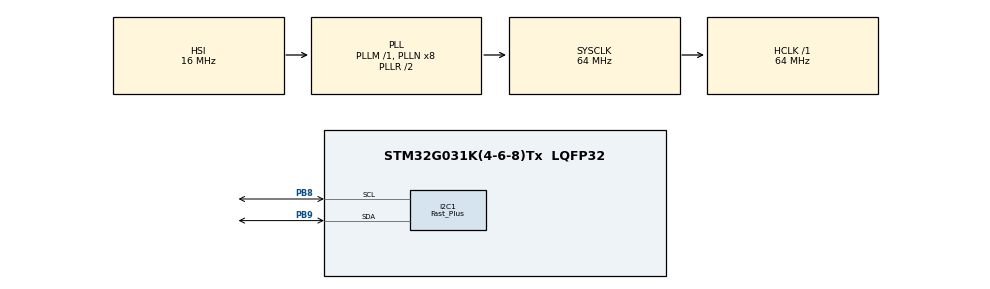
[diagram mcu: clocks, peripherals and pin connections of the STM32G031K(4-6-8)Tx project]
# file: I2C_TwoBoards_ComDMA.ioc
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Dma.I2C1_RX.1.Direction=DMA_PERIPH_TO_MEMORY
Dma.I2C1_RX.1.EventEnable=DISABLE
Dma.I2C1_RX.1.Instance=DMA1_Channel2
Dma.I2C1_RX.1.MemDataAlignment=DMA_MDATAALIGN_BYTE
Dma.I2C1_RX.1.MemInc=DMA_MINC_ENABLE
Dma.I2C1_RX.1.Mode=DMA_NORMAL
Dma.I2C1_RX.1.PeriphDataAlignment=DMA_PDATAALIGN_BYTE
Dma.I2C1_RX.1.PeriphInc=DMA_PINC_DISABLE
Dma.I2C1_RX.1.Polarity=HAL_DMAMUX_REQ_GEN_RISING
Dma.I2C1_RX.1.Priority=DMA_PRIORITY_HIGH
Dma.I2C1_RX.1.RequestNumber=1
Dma.I2C1_RX.1.SignalID=NONE
Dma.I2C1_RX.1.SyncEnable=DISABLE
Dma.I2C1_RX.1.SyncPolarity=HAL_DMAMUX_SYNC_NO_EVENT
Dma.I2C1_RX.1.SyncRequestNumber=1
Dma.I2C1_RX.1.SyncSignalID=NONE
Dma.I2C1_TX.0.Direction=DMA_MEMORY_TO_PERIPH
Dma.I2C1_TX.0.EventEnable=DISABLE
Dma.I2C1_TX.0.Instance=DMA1_Channel1
Dma.I2C1_TX.0.MemDataAlignment=DMA_MDATAALIGN_BYTE
Dma.I2C1_TX.0.MemInc=DMA_MINC_ENABLE
Dma.I2C1_TX.0.Mode=DMA_NORMAL
Dma.I2C1_TX.0.PeriphDataAlignment=DMA_PDATAALIGN_BYTE
Dma.I2C1_TX.0.PeriphInc=DMA_PINC_DISABLE
Dma.I2C1_TX.0.Polarity=HAL_DMAMUX_REQ_GEN_RISING
Dma.I2C1_TX.0.Priority=DMA_PRIORITY_LOW
Dma.I2C1_TX.0.RequestNumber=1
Dma.I2C1_TX.0.SignalID=NONE
Dma.I2C1_TX.0.SyncEnable=DISABLE
Dma.I2C1_TX.0.SyncPolarity=HAL_DMAMUX_SYNC_NO_EVENT
Dma.I2C1_TX.0.SyncRequestNumber=1
Dma.I2C1_TX.0.SyncSignalID=NONE
Dma.Request0=I2C1_TX
Dma.Request1=I2C1_RX
I2C1.AddressingMode=I2C_ADDRESSINGMODE_10BIT
I2C1.Analog_Filter=I2C_ANALOGFILTER_ENABLE
I2C1.DualAddressMode=I2C_DUALADDRESS_DISABLE
I2C1.GeneralCallMode=I2C_GENERALCALL_DISABLE
I2C1.I2C_Coeff_DF=0x0
I2C1.I2C_Fall_Time=2
I2C1.I2C_Rise_Time=26
I2C1.I2C_Speed_Mode=I2C_Fast_Plus
I2C1.NoStretchMode=I2C_NOSTRETCH_DISABLE
I2C1.OwnAddress=I2C_ADDRESS
I2C1.Speed=1000
Mcu.Family=STM32G0
Mcu.Name=STM32G031K(4-6-8)Tx
Mcu.Package=LQFP32
Mcu.UserConstants=I2C_ADDRESS,0x30F
NVIC.DMA1_Channel1_IRQn=true\:0\:0\:false\:false\:true\:true\:true\:true
NVIC.DMA1_Channel2_3_IRQn=true\:0\:0\:false\:false\:true\:true\:true\:true
NVIC.I2C1_IRQn=true\:0\:0\:false\:false\:true\:true\:true\:true
PB8.GPIO_Pu=GPIO_PULLUP
PB8.Mode=I2C
PB8.Signal=I2C1_SCL
PB9.GPIO_Pu=GPIO_PULLUP
PB9.Mode=I2C
PB9.Signal=I2C1_SDA
ProjectManager.HeapSize=0x200
ProjectManager.StackSize=0x400
ProjectManager.TargetToolchain=EWARM V8.50
RCC.ADCFreq_Value=64000000
RCC.AHBFreq_Value=64000000
RCC.CortexFreq_Value=64000000
RCC.EXTERNAL_CLOCK_VALUE=48000000
RCC.HCLKFreq_Value=64000000
RCC.HSE_VALUE=8000000
RCC.HSI_VALUE=16000000
RCC.LSE_VALUE=32768
RCC.SYSCLKFreq_VALUE=64000000
RCC.SYSCLKSource=RCC_SYSCLKSOURCE_PLLCLK
RCC.VCOOutputFreq_Value=128000000
board=custom

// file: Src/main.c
/* USER CODE BEGIN Header */
/**
  ******************************************************************************
  * @file    I2C/I2C_TwoBoards_ComDMA/Src/main.c
  * @author  MCD Application Team
  * @brief   This sample code shows how to use STM32G0xx I2C HAL API to transmit
  *          and receive a data buffer with a communication process based on
  *          DMA transfer.
  *          The communication is done using 2 Boards.
  ******************************************************************************
  * @attention
  *
  * Copyright (c) 2019-2020 STMicroelectronics.
  * All rights reserved.
  *
  * This software is licensed under terms that can be found in the LICENSE file
  * in the root directory of this software component.
  * If no LICENSE file comes with this software, it is provided AS-IS.
  *
  ******************************************************************************
  */
/* USER CODE END Header */
#include "main.h"

/* USER CODE BEGIN PD */
/* Uncomment this line to use the board as master, if not it is used as slave */
//#define MASTER_BOARD
/* USER CODE END PD */

I2C_HandleTypeDef hi2c1;
DMA_HandleTypeDef hdma_i2c1_tx;
DMA_HandleTypeDef hdma_i2c1_rx;

/* USER CODE BEGIN PV */
/* Buffer used for transmission */
uint8_t aTxBuffer[] = " ****I2C_TwoBoards communication based on DMA****  ****I2C_TwoBoards communication based on DMA****  ****I2C_TwoBoards communication based on DMA**** ";

/* Buffer used for reception */
uint8_t aRxBuffer[RXBUFFERSIZE];
/* USER CODE END PV */

void SystemClock_Config(void);
static void MX_GPIO_Init(void);
static void MX_DMA_Init(void);
static void MX_I2C1_Init(void);
/* USER CODE BEGIN PFP */
/* Private function prototypes -----------------------------------------------*/
static uint16_t Buffercmp(uint8_t *pBuffer1, uint8_t *pBuffer2, uint16_t BufferLength);

/* USER CODE END PFP */

int main(void)
{
  /* USER CODE BEGIN 1 */
#ifdef MASTER_BOARD
  GPIO_InitTypeDef  GPIO_InitStruct;
#endif
  /* STM32G0xx HAL library initialization:
       - Configure the Flash prefetch
       - Systick timer is configured by default as source of time base, but user
         can eventually implement his proper time base source (a general purpose
         timer for example or other time source), keeping in mind that Time base
         duration should be kept 1ms since PPP_TIMEOUT_VALUEs are defined and
         handled in milliseconds basis.
       - Low Level Initialization
     */
  /* USER CODE END 1 */

  /* MCU Configuration--------------------------------------------------------*/

  /* Reset of all peripherals, Initializes the Flash interface and the Systick. */
  HAL_Init();

  /* Configure the system clock */
  SystemClock_Config();

  /* Initialize all configured peripherals */
  MX_GPIO_Init();
  MX_DMA_Init();
  MX_I2C1_Init();
  /* USER CODE BEGIN 2 */
  /* Configure LED3 */
  BSP_LED_Init(LED3);

#ifdef MASTER_BOARD

  /* Configure PA.15 (Arduino D2) */
  GPIO_InitStruct.Pin = GPIO_PIN_15;
  GPIO_InitStruct.Pull = GPIO_PULLUP;
  GPIO_InitStruct.Mode = GPIO_MODE_INPUT;
  GPIO_InitStruct.Speed = GPIO_SPEED_FREQ_VERY_HIGH;

  /* Enable GPIOA clock */
  __HAL_RCC_GPIOA_CLK_ENABLE();

  HAL_GPIO_Init(GPIOA, &GPIO_InitStruct);
  /* USER CODE END 2 */

  /* Infinite loop */
  /* USER CODE BEGIN WHILE */
  /* Wait Until PA.15 (Arduino D2) is connected to GND */
  while (HAL_GPIO_ReadPin(GPIOA, GPIO_PIN_15) != GPIO_PIN_RESET)
  {
  }
  /* Wait Until PA.15 (Arduino D2) is de-connected from GND */
  while (HAL_GPIO_ReadPin(GPIOA, GPIO_PIN_15) != GPIO_PIN_SET)
  {
  }

  /* The board sends the message and expects to receive it back */

  /*##- Start the transmission process #####################################*/
  /* While the I2C in reception process, user can transmit data through
     "aTxBuffer" buffer */
  do
  {
    if (HAL_I2C_Master_Transmit_DMA(&hi2c1, (uint16_t)I2C_ADDRESS, (uint8_t *)aTxBuffer, TXBUFFERSIZE) != HAL_OK)
    {
      /* Error_Handler() function is called when error occurs. */
      Error_Handler();
    }

    /*##- Wait for the end of the transfer #################################*/
    /*  Before starting a new communication transfer, you need to check the current
        state of the peripheral; if it’s busy you need to wait for the end of current
        transfer before starting a new one.
        For simplicity reasons, this example is just waiting till the end of the
        transfer, but application may perform other tasks while transfer operation
        is ongoing. */
    while (HAL_I2C_GetState(&hi2c1) != HAL_I2C_STATE_READY)
    {
    }

    /* When Acknowledge failure occurs (Slave don't acknowledge it's address)
       Master restarts communication */
  }
  while (HAL_I2C_GetError(&hi2c1) == HAL_I2C_ERROR_AF);

  HAL_Delay(1000);

  /* Wait Until PA.15 (Arduino D2) is connected to GND */
  while (HAL_GPIO_ReadPin(GPIOA, GPIO_PIN_15) != GPIO_PIN_RESET)
  {
  }
  /* Wait Until PA.15 (Arduino D2) is de-connected from GND */
  while (HAL_GPIO_ReadPin(GPIOA, GPIO_PIN_15) != GPIO_PIN_SET)
  {
  }

  /*##- Put I2C peripheral in reception process ###########################*/
  do
  {
    if (HAL_I2C_Master_Receive_DMA(&hi2c1, (uint16_t)I2C_ADDRESS, (uint8_t *)aRxBuffer, RXBUFFERSIZE) != HAL_OK)
    {
      /* Error_Handler() function is called when error occurs. */
      Error_Handler();
    }

    /*##- Wait for the end of the transfer #################################*/
    /*  Before starting a new communication transfer, you need to check the current
        state of the peripheral; if it’s busy you need to wait for the end of current
        transfer before starting a new one.
        For simplicity reasons, this example is just waiting till the end of the
        transfer, but application may perform other tasks while transfer operation
        is ongoing. */
    while (HAL_I2C_GetState(&hi2c1) != HAL_I2C_STATE_READY)
    {
    }

    /* When Acknowledge failure occurs (Slave don't acknowledge it's address)
       Master restarts communication */
  }
  while (HAL_I2C_GetError(&hi2c1) == HAL_I2C_ERROR_AF);

#else

  /* The board receives the message and sends it back */

  /*##- Put I2C peripheral in reception process ###########################*/
  if (HAL_I2C_Slave_Receive_DMA(&hi2c1, (uint8_t *)aRxBuffer, RXBUFFERSIZE) != HAL_OK)
  {
    /* Transfer error in reception process */
    Error_Handler();
  }

  /*##- Wait for the end of the transfer ###################################*/
  /*  Before starting a new communication transfer, you need to check the current
      state of the peripheral; if it’s busy you need to wait for the end of current
      transfer before starting a new one.
      For simplicity reasons, this example is just waiting till the end of the
      transfer, but application may perform other tasks while transfer operation
      is ongoing. */
  while (HAL_I2C_GetState(&hi2c1) != HAL_I2C_STATE_READY)
  {
  }

  /*##- Start the transmission process #####################################*/
  /* While the I2C in reception process, user can transmit data through
     "aTxBuffer" buffer */
  if (HAL_I2C_Slave_Transmit_DMA(&hi2c1, (uint8_t *)aTxBuffer, TXBUFFERSIZE) != HAL_OK)
  {
    /* Transfer error in transmission process */
    Error_Handler();
  }

#endif /* MASTER_BOARD */

  /*##- Wait for the end of the transfer ###################################*/
  /*  Before starting a new communication transfer, you need to check the current
      state of the peripheral; if it’s busy you need to wait for the end of current
      transfer before starting a new one.
      For simplicity reasons, this example is just waiting till the end of the
      transfer, but application may perform other tasks while transfer operation
      is ongoing. */
  while (HAL_I2C_GetState(&hi2c1) != HAL_I2C_STATE_READY)
  {
  }

  /*##- Compare the sent and received buffers ##############################*/
  if (Buffercmp((uint8_t *)aTxBuffer, (uint8_t *)aRxBuffer, RXBUFFERSIZE))
  {
    /* Processing Error */
    Error_Handler();
  }

  /* Infinite loop */
  while (1)
  {
    /* USER CODE END WHILE */

  }
}

void SystemClock_Config(void)
{
  RCC_OscInitTypeDef RCC_OscInitStruct = {0};
  RCC_ClkInitTypeDef RCC_ClkInitStruct = {0};

  /** Configure the main internal regulator output voltage
  */
  HAL_PWREx_ControlVoltageScaling(PWR_REGULATOR_VOLTAGE_SCALE1);

  /** Initializes the RCC Oscillators according to the specified parameters
  * in the RCC_OscInitTypeDef structure.
  */
  RCC_OscInitStruct.OscillatorType = RCC_OSCILLATORTYPE_HSI;
  RCC_OscInitStruct.HSIState = RCC_HSI_ON;
  RCC_OscInitStruct.HSIDiv = RCC_HSI_DIV1;
  RCC_OscInitStruct.HSICalibrationValue = RCC_HSICALIBRATION_DEFAULT;
  RCC_OscInitStruct.PLL.PLLState = RCC_PLL_ON;
  RCC_OscInitStruct.PLL.PLLSource = RCC_PLLSOURCE_HSI;
  RCC_OscInitStruct.PLL.PLLM = RCC_PLLM_DIV1;
  RCC_OscInitStruct.PLL.PLLN = 8;
  RCC_OscInitStruct.PLL.PLLP = RCC_PLLP_DIV2;
  RCC_OscInitStruct.PLL.PLLQ = RCC_PLLQ_DIV2;
  RCC_OscInitStruct.PLL.PLLR = RCC_PLLR_DIV2;
  if (HAL_RCC_OscConfig(&RCC_OscInitStruct) != HAL_OK)
  {
    Error_Handler();
  }

  /** Initializes the CPU, AHB and APB buses clocks
  */
  RCC_ClkInitStruct.ClockType = RCC_CLOCKTYPE_HCLK|RCC_CLOCKTYPE_SYSCLK
                              |RCC_CLOCKTYPE_PCLK1;
  RCC_ClkInitStruct.SYSCLKSource = RCC_SYSCLKSOURCE_PLLCLK;
  RCC_ClkInitStruct.AHBCLKDivider = RCC_SYSCLK_DIV1;
  RCC_ClkInitStruct.APB1CLKDivider = RCC_HCLK_DIV1;

  if (HAL_RCC_ClockConfig(&RCC_ClkInitStruct, FLASH_LATENCY_2) != HAL_OK)
  {
    Error_Handler();
  }
}

static void MX_I2C1_Init(void)
{

  hi2c1.Instance = I2C1;
  hi2c1.Init.Timing = 0x00303D5B;
  hi2c1.Init.OwnAddress1 = I2C_ADDRESS;
  hi2c1.Init.AddressingMode = I2C_ADDRESSINGMODE_10BIT;
  hi2c1.Init.DualAddressMode = I2C_DUALADDRESS_DISABLE;
  hi2c1.Init.OwnAddress2 = 0;
  hi2c1.Init.OwnAddress2Masks = I2C_OA2_NOMASK;
  hi2c1.Init.GeneralCallMode = I2C_GENERALCALL_DISABLE;
  hi2c1.Init.NoStretchMode = I2C_NOSTRETCH_DISABLE;
  if (HAL_I2C_Init(&hi2c1) != HAL_OK)
  {
    Error_Handler();
  }

  /** Configure Analogue filter
  */
  if (HAL_I2CEx_ConfigAnalogFilter(&hi2c1, I2C_ANALOGFILTER_ENABLE) != HAL_OK)
  {
    Error_Handler();
  }

  /** Configure Digital filter
  */
  if (HAL_I2CEx_ConfigDigitalFilter(&hi2c1, 0x0) != HAL_OK)
  {
    Error_Handler();
  }

  /** I2C Fast mode Plus enable
  */
  HAL_I2CEx_EnableFastModePlus(I2C_FASTMODEPLUS_I2C1);

}

static void MX_DMA_Init(void)
{

  /* DMA controller clock enable */
  __HAL_RCC_DMA1_CLK_ENABLE();

  /* DMA interrupt init */
  /* DMA1_Channel1_IRQn interrupt configuration */
  HAL_NVIC_SetPriority(DMA1_Channel1_IRQn, 0, 0);
  HAL_NVIC_EnableIRQ(DMA1_Channel1_IRQn);
  /* DMA1_Channel2_3_IRQn interrupt configuration */
  HAL_NVIC_SetPriority(DMA1_Channel2_3_IRQn, 0, 0);
  HAL_NVIC_EnableIRQ(DMA1_Channel2_3_IRQn);

}

static void MX_GPIO_Init(void)
{

  /* GPIO Ports Clock Enable */
  __HAL_RCC_GPIOB_CLK_ENABLE();

}

/* USER CODE BEGIN 4 */
/**
  * @brief  Compares two buffers.
  * @param  pBuffer1, pBuffer2: buffers to be compared.
  * @param  BufferLength: buffer's length
  * @retval 0  : pBuffer1 identical to pBuffer2
  *         >0 : pBuffer1 differs from pBuffer2
  */
static uint16_t Buffercmp(uint8_t *pBuffer1, uint8_t *pBuffer2, uint16_t BufferLength)
{
  while (BufferLength--)
  {
    if ((*pBuffer1) != *pBuffer2)
    {
      return BufferLength;
    }
    pBuffer1++;
    pBuffer2++;
  }

  return 0;
}

/**
  * @brief  Tx Transfer completed callback.
  * @param  I2cHandle: I2C handle.
  * @note   This example shows a simple way to report end of DMA Tx transfer, and
  *         you can add your own implementation.
  * @retval None
  */
#ifdef MASTER_BOARD
void HAL_I2C_MasterTxCpltCallback(I2C_HandleTypeDef *I2cHandle)
{
  /* Toggle LED3: Transfer in transmission process is correct */
  BSP_LED_Toggle(LED3);
}
#else
void HAL_I2C_SlaveTxCpltCallback(I2C_HandleTypeDef *I2cHandle)
{
  /* Toggle LED3: Transfer in transmission process is correct */
  BSP_LED_Toggle(LED3);
}
#endif /* MASTER_BOARD */

/**
  * @brief  Rx Transfer completed callback.
  * @param  I2cHandle: I2C handle
  * @note   This example shows a simple way to report end of DMA Rx transfer, and
  *         you can add your own implementation.
  * @retval None
  */
#ifdef MASTER_BOARD
void HAL_I2C_MasterRxCpltCallback(I2C_HandleTypeDef *I2cHandle)
{
  /* Toggle LED3: Transfer in reception process is correct */
  BSP_LED_Toggle(LED3);
}
#else
void HAL_I2C_SlaveRxCpltCallback(I2C_HandleTypeDef *I2cHandle)
{
  /* Toggle LED3: Transfer in reception process is correct */
  BSP_LED_Toggle(LED3);
}
#endif /* MASTER_BOARD */

/**
  * @brief  I2C error callbacks.
  * @param  I2cHandle: I2C handle
  * @note   This example shows a simple way to report transfer error, and you can
  *         add your own implementation.
  * @retval None
  */
void HAL_I2C_ErrorCallback(I2C_HandleTypeDef *I2cHandle)
{
  /** Error_Handler() function is called when error occurs.
    * 1- When Slave doesn't acknowledge its address, Master restarts communication.
    * 2- When Master doesn't acknowledge the last data transferred, Slave doesn't care in this example.
    */
  if (HAL_I2C_GetError(I2cHandle) != HAL_I2C_ERROR_AF)
  {
    Error_Handler();
  }
}

/* USER CODE END 4 */

void Error_Handler(void)
{
  /* USER CODE BEGIN Error_Handler_Debug */
  /* Error if LED3 is slowly blinking (1 sec. period) */
  while (1)
  {
    BSP_LED_Toggle(LED3);
    HAL_Delay(1000);
  }
  /* USER CODE END Error_Handler_Debug */
}

#ifdef  USE_FULL_ASSERT
/**
  * @brief  Reports the name of the source file and the source line number
  *         where the assert_param error has occurred.
  * @param  file: pointer to the source file name
  * @param  line: assert_param error line source number
  * @retval None
  */
void assert_failed(uint8_t *file, uint32_t line)
{
  /* USER CODE BEGIN 6 */
  /* User can add his own implementation to report the file name and line number,
     ex: printf("Wrong parameters value: file %s on line %d\r\n", file, line) */
  Error_Handler();
  /* USER CODE END 6 */
}
#endif /* USE_FULL_ASSERT */
